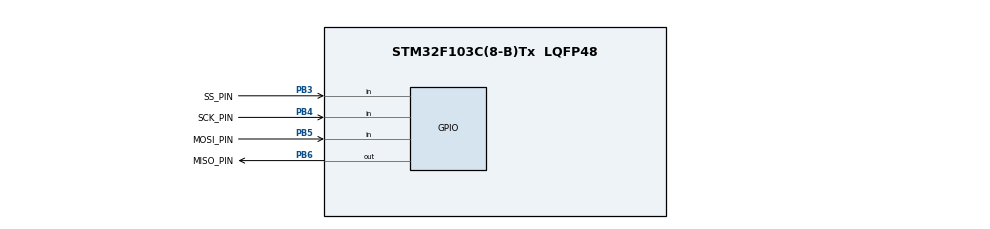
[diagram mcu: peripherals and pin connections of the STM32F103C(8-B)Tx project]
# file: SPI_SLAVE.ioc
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Mcu.Family=STM32F1
Mcu.Name=STM32F103C(8-B)Tx
Mcu.Package=LQFP48
NVIC.PriorityGroup=NVIC_PRIORITYGROUP_4
PA13.Mode=Serial_Wire
PA13.Signal=SYS_JTMS-SWDIO
PA14.Mode=Serial_Wire
PA14.Signal=SYS_JTCK-SWCLK
PB3.GPIO_Label=SS_PIN
PB3.GPIO_PuPd=GPIO_PULLDOWN
PB3.Signal=GPIO_Input
PB4.GPIO_Label=SCK_PIN
PB4.GPIO_PuPd=GPIO_PULLDOWN
PB4.Signal=GPIO_Input
PB5.GPIO_Label=MOSI_PIN
PB5.Signal=GPIO_Input
PB6.GPIO_Label=MISO_PIN
PB6.Signal=GPIO_Output
ProjectManager.HeapSize=0x200
ProjectManager.StackSize=0x400
ProjectManager.TargetToolchain=MDK-ARM V5.32
RCC.APB1Freq_Value=8000000
RCC.APB2Freq_Value=8000000
board=custom

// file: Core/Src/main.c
/* USER CODE BEGIN Header */
/**
  ******************************************************************************
  * @file           : main.c
  * @brief          : Main program body
  ******************************************************************************
  * @attention
  *
  * Copyright (c) 2023 STMicroelectronics.
  * All rights reserved.
  *
  * This software is licensed under terms that can be found in the LICENSE file
  * in the root directory of this software component.
  * If no LICENSE file comes with this software, it is provided AS-IS.
  *
  ******************************************************************************
  */
/* USER CODE END Header */
#include "main.h"
#include "string.h"

/* USER CODE BEGIN PM */
#define read_SS() READ_BIT(GPIOB->IDR, GPIO_IDR_IDR3)
#define read_SCK() READ_BIT(GPIOB->IDR, GPIO_IDR_IDR4)
#define read_MOSI() READ_BIT(GPIOB->IDR, GPIO_IDR_IDR5)
#define write_MISO(x) x? SET_BIT(GPIOB->ODR, GPIO_ODR_ODR6):CLEAR_BIT(GPIOB->ODR, GPIO_ODR_ODR6)
//#define read_SS() (GPIOB->IDR & (1<<3))?1:0
//#define read_SCK() (GPIOB->IDR & (1<<4))?1:0
//#define read_MOSI() (GPIOB->IDR & (1<<5))?1:0
//#define write_MISO(x) (x)?(GPIOB->ODR|= 1<<6):(GPIOB->ODR &= ~(1<<6))
/* USER CODE END PM */

/* USER CODE BEGIN PV */
volatile uint8_t rev ;

/* USER CODE END PV */

void SystemClock_Config(void);
static void MX_GPIO_Init(void);
/* USER CODE BEGIN PFP */
uint8_t SPI_trans_recei_slave(uint8_t byte_out);
/* USER CODE END PFP */

int main(void)
{

  /* MCU Configuration--------------------------------------------------------*/

  /* Reset of all peripherals, Initializes the Flash interface and the Systick. */
  HAL_Init();

  /* Configure the system clock */
  SystemClock_Config();

  /* Initialize all configured peripherals */
  MX_GPIO_Init();

  /* Infinite loop */
  while (1)
  {

    /* USER CODE BEGIN 3 */
		rev = SPI_trans_recei_slave(20);
  }
  /* USER CODE END 3 */
}

void SystemClock_Config(void)
{
  RCC_OscInitTypeDef RCC_OscInitStruct = {0};
  RCC_ClkInitTypeDef RCC_ClkInitStruct = {0};

  /** Initializes the RCC Oscillators according to the specified parameters
  * in the RCC_OscInitTypeDef structure.
  */
  RCC_OscInitStruct.OscillatorType = RCC_OSCILLATORTYPE_HSI;
  RCC_OscInitStruct.HSIState = RCC_HSI_ON;
  RCC_OscInitStruct.HSICalibrationValue = RCC_HSICALIBRATION_DEFAULT;
  RCC_OscInitStruct.PLL.PLLState = RCC_PLL_NONE;
  if (HAL_RCC_OscConfig(&RCC_OscInitStruct) != HAL_OK)
  {
    Error_Handler();
  }

  /** Initializes the CPU, AHB and APB buses clocks
  */
  RCC_ClkInitStruct.ClockType = RCC_CLOCKTYPE_HCLK|RCC_CLOCKTYPE_SYSCLK
                              |RCC_CLOCKTYPE_PCLK1|RCC_CLOCKTYPE_PCLK2;
  RCC_ClkInitStruct.SYSCLKSource = RCC_SYSCLKSOURCE_HSI;
  RCC_ClkInitStruct.AHBCLKDivider = RCC_SYSCLK_DIV1;
  RCC_ClkInitStruct.APB1CLKDivider = RCC_HCLK_DIV1;
  RCC_ClkInitStruct.APB2CLKDivider = RCC_HCLK_DIV1;

  if (HAL_RCC_ClockConfig(&RCC_ClkInitStruct, FLASH_LATENCY_0) != HAL_OK)
  {
    Error_Handler();
  }
}

static void MX_GPIO_Init(void)
{
  GPIO_InitTypeDef GPIO_InitStruct = {0};

  /* GPIO Ports Clock Enable */
  __HAL_RCC_GPIOA_CLK_ENABLE();
  __HAL_RCC_GPIOB_CLK_ENABLE();

  /*Configure GPIO pin Output Level */
  HAL_GPIO_WritePin(MISO_PIN_GPIO_Port, MISO_PIN_Pin, GPIO_PIN_RESET);

  /*Configure GPIO pins : SS_PIN_Pin SCK_PIN_Pin */
  GPIO_InitStruct.Pin = SS_PIN_Pin|SCK_PIN_Pin;
  GPIO_InitStruct.Mode = GPIO_MODE_INPUT;
  GPIO_InitStruct.Pull = GPIO_NOPULL;
  HAL_GPIO_Init(GPIOB, &GPIO_InitStruct);

  /*Configure GPIO pin : MOSI_PIN_Pin */
  GPIO_InitStruct.Pin = MOSI_PIN_Pin;
  GPIO_InitStruct.Mode = GPIO_MODE_INPUT;
  GPIO_InitStruct.Pull = GPIO_NOPULL;
  HAL_GPIO_Init(MOSI_PIN_GPIO_Port, &GPIO_InitStruct);

  /*Configure GPIO pin : MISO_PIN_Pin */
  GPIO_InitStruct.Pin = MISO_PIN_Pin;
  GPIO_InitStruct.Mode = GPIO_MODE_OUTPUT_PP;
  GPIO_InitStruct.Pull = GPIO_NOPULL;
  GPIO_InitStruct.Speed = GPIO_SPEED_FREQ_LOW;
  HAL_GPIO_Init(MISO_PIN_GPIO_Port, &GPIO_InitStruct);

}

uint8_t SPI_trans_recei_slave(uint8_t byte_out)
{
	uint8_t byte_in = 0;
	uint8_t result, i ;

	while(read_SS() == 1);
	for(i = 0x80; i>0; i = i>>1)
	{
		result = byte_out & i;
		write_MISO(result);
		while(read_SCK() == 0);
		if(read_MOSI() == 1) byte_in |= i;
		while(read_SCK() == 1);
	}
	return byte_in;
}

void Error_Handler(void)
{
  __disable_irq();
  while (1)
  {
  }
}
